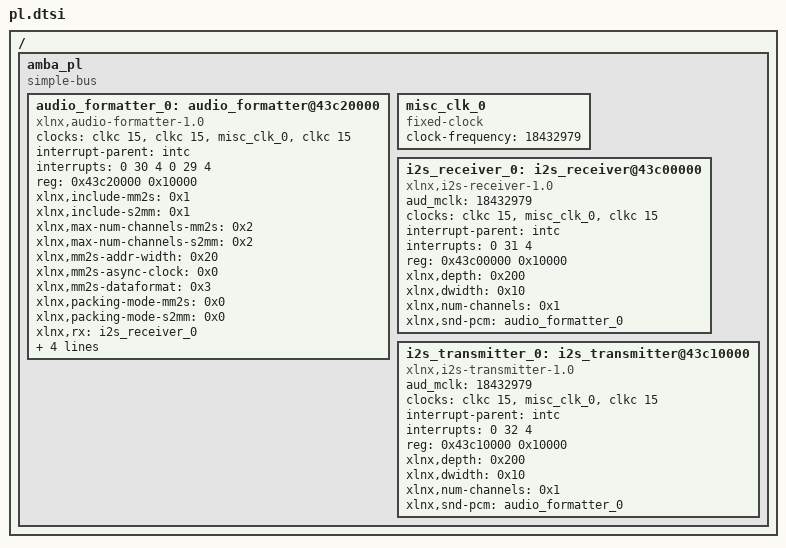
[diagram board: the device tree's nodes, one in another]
/*
 * CAUTION: This file is automatically generated by Xilinx.
 * Version: XSCT 2019.1
 * Today is: Wed Nov 13 22:32:44 2024
 */


/ {
	amba_pl: amba_pl {
		#address-cells = <1>;
		#size-cells = <1>;
		compatible = "simple-bus";
		ranges ;
		audio_formatter_0: audio_formatter@43c20000 {
			clock-names = "s_axi_lite_aclk", "m_axis_mm2s_aclk", "aud_mclk", "s_axis_s2mm_aclk";
			clocks = <&clkc 15>, <&clkc 15>, <&misc_clk_0>, <&clkc 15>;
			compatible = "xlnx,audio-formatter-1.0", "xlnx,audio-formatter-1.0";
			interrupt-names = "irq_mm2s", "irq_s2mm";
			interrupt-parent = <&intc>;
			interrupts = <0 30 4 0 29 4>;
			reg = <0x43c20000 0x10000>;
			xlnx,include-mm2s = <0x1>;
			xlnx,include-s2mm = <0x1>;
			xlnx,max-num-channels-mm2s = <0x2>;
			xlnx,max-num-channels-s2mm = <0x2>;
			xlnx,mm2s-addr-width = <0x20>;
			xlnx,mm2s-async-clock = <0x0>;
			xlnx,mm2s-dataformat = <0x3>;
			xlnx,packing-mode-mm2s = <0x0>;
			xlnx,packing-mode-s2mm = <0x0>;
			xlnx,rx = <&i2s_receiver_0>;
			xlnx,s2mm-addr-width = <0x20>;
			xlnx,s2mm-async-clock = <0x0>;
			xlnx,s2mm-dataformat = <0x1>;
			xlnx,tx = <&i2s_transmitter_0>;
		};
		misc_clk_0: misc_clk_0 {
			#clock-cells = <0>;
			clock-frequency = <18432979>;
			compatible = "fixed-clock";
		};
		i2s_receiver_0: i2s_receiver@43c00000 {
			aud_mclk = <18432979>;
			clock-names = "s_axi_ctrl_aclk", "aud_mclk", "m_axis_aud_aclk";
			clocks = <&clkc 15>, <&misc_clk_0>, <&clkc 15>;
			compatible = "xlnx,i2s-receiver-1.0", "xlnx,i2s-receiver-1.0";
			interrupt-names = "irq";
			interrupt-parent = <&intc>;
			interrupts = <0 31 4>;
			reg = <0x43c00000 0x10000>;
			xlnx,depth = <0x200>;
			xlnx,dwidth = <0x10>;
			xlnx,num-channels = <0x1>;
			xlnx,snd-pcm = <&audio_formatter_0>;
		};
		i2s_transmitter_0: i2s_transmitter@43c10000 {
			aud_mclk = <18432979>;
			clock-names = "s_axi_ctrl_aclk", "aud_mclk", "s_axis_aud_aclk";
			clocks = <&clkc 15>, <&misc_clk_0>, <&clkc 15>;
			compatible = "xlnx,i2s-transmitter-1.0", "xlnx,i2s-transmitter-1.0";
			interrupt-names = "irq";
			interrupt-parent = <&intc>;
			interrupts = <0 32 4>;
			reg = <0x43c10000 0x10000>;
			xlnx,depth = <0x200>;
			xlnx,dwidth = <0x10>;
			xlnx,num-channels = <0x1>;
			xlnx,snd-pcm = <&audio_formatter_0>;
		};
	};
};
